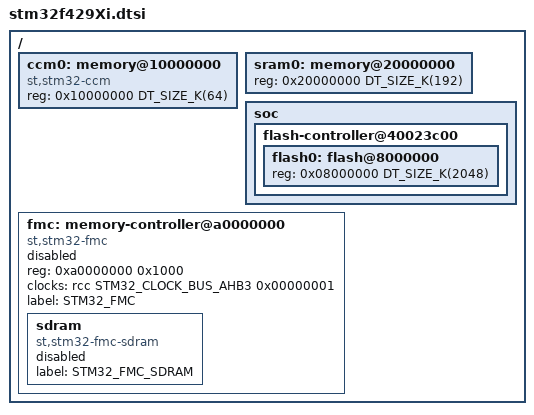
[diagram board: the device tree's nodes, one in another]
/*
 * Copyright (c) 2018 Linaro Limited
 *
 * SPDX-License-Identifier: Apache-2.0
 */

#include <mem.h>
#include <st/f4/stm32f429.dtsi>
#include <dt-bindings/memory-controller/stm32-fmc-sdram.h>

/ {
	ccm0: memory@10000000 {
		compatible = "st,stm32-ccm";
		reg = <0x10000000 DT_SIZE_K(64)>;
	};

	sram0: memory@20000000 {
		reg = <0x20000000 DT_SIZE_K(192)>;
	};

	soc {
		flash-controller@40023c00 {
			flash0: flash@8000000 {
				reg = <0x08000000 DT_SIZE_K(2048)>;
			};
		};
	};

	fmc: memory-controller@a0000000 {
		compatible = "st,stm32-fmc";
		reg = <0xa0000000 0x1000>;
		clocks = <&rcc STM32_CLOCK_BUS_AHB3 0x00000001>;
		label = "STM32_FMC";
		status = "disabled";

		sdram: sdram {
			compatible = "st,stm32-fmc-sdram";
			#address-cells = <1>;
			#size-cells = <0>;
			label = "STM32_FMC_SDRAM";
			status = "disabled";
		};
	};

};
